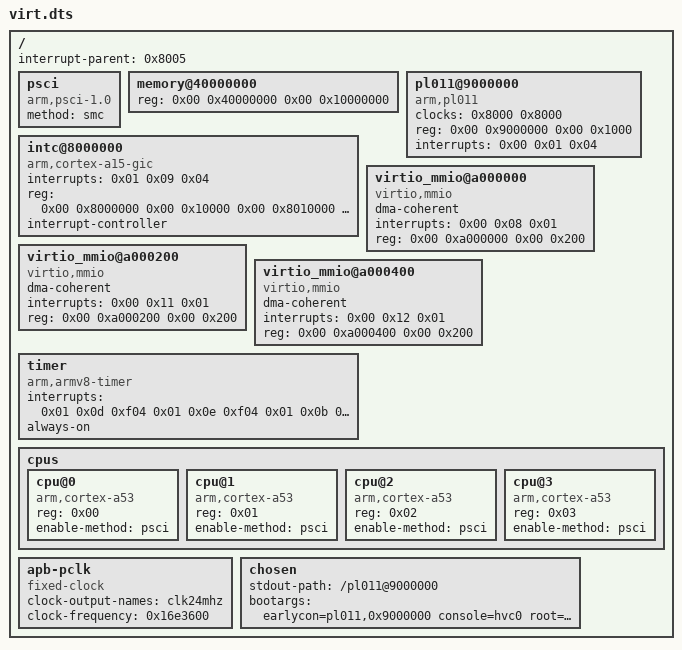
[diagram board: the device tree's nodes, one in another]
/dts-v1/;

/ {
	#size-cells = <0x02>;
	#address-cells = <0x02>;
	interrupt-parent = <0x8005>;

	psci {
		method = "smc";
		compatible = "arm,psci-1.0\0arm,psci-0.2\0arm,psci";
	};

	/* The size field (0x10000000) is only a placeholder: the hypervisor
	 * computes the guest RAM size at boot from the host's usable RAM and
	 * the number of physical CPUs, and rewrites this reg entry when
	 * loading this DTB into guest RAM (see vm.rs `create_vm`). */
	memory@40000000 {
		reg = <0x00 0x40000000 0x00 0x10000000>;
		device_type = "memory";
	};

	pl011@9000000 {
		clock-names = "uartclk\0apb_pclk";
		clocks = <0x8000 0x8000>;
		reg = <0x00 0x9000000 0x00 0x1000>;
		interrupts = <0x00 0x01 0x04>;
		compatible = "arm,pl011\0arm,primecell";
	};

	intc@8000000 {
		#interrupt-cells = <0x03>;
		phandle = <0x8005>;
		interrupts = <0x01 0x09 0x04>;
		reg = <0x00 0x8000000 0x00 0x10000 0x00 0x8010000 0x00 0x10000 0x00 0x8030000 0x00 0x10000 0x00 0x8040000 0x00 0x10000>;
		compatible = "arm,cortex-a15-gic";
		interrupt-controller;
	};

	virtio_mmio@a000000 {
		dma-coherent;
		interrupts = <0x00 0x08 0x01>;
		reg = <0x00 0xa000000 0x00 0x200>;
		compatible = "virtio,mmio";
	};

	virtio_mmio@a000200 {
		dma-coherent;
		interrupts = <0x00 0x11 0x01>;
		reg = <0x00 0xa000200 0x00 0x200>;
		compatible = "virtio,mmio";
	};

	virtio_mmio@a000400 {
		dma-coherent;
		interrupts = <0x00 0x12 0x01>;
		reg = <0x00 0xa000400 0x00 0x200>;
		compatible = "virtio,mmio";
	};

	timer {
		interrupts = <0x01 0x0d 0xf04 0x01 0x0e 0xf04 0x01 0x0b 0xf04 0x01 0x0a 0xf04>;
		always-on;
		compatible = "arm,armv8-timer\0arm,armv7-timer";
	};

	cpus {
		#size-cells = <0x00>;
		#address-cells = <0x01>;
		cpu@0 {
			phandle = <0x8004>;
			reg = <0x00>;
			enable-method = "psci";
			compatible = "arm,cortex-a53";
			device_type = "cpu";
		};

		cpu@1 {
			reg = <0x01>;
			enable-method = "psci";
			compatible = "arm,cortex-a53";
			device_type = "cpu";
		};

		cpu@2 {
			reg = <0x02>;
			enable-method = "psci";
			compatible = "arm,cortex-a53";
			device_type = "cpu";
		};

		cpu@3 {
			reg = <0x03>;
			enable-method = "psci";
			compatible = "arm,cortex-a53";
			device_type = "cpu";
		};
	};

	apb-pclk {
		phandle = <0x8000>;
		clock-output-names = "clk24mhz";
		clock-frequency = <0x16e3600>;
		#clock-cells = <0x00>;
		compatible = "fixed-clock";
	};

	chosen {
		stdout-path = "/pl011@9000000";
		/* rootflags=init_itable=0: every `cargo run-qemu` re-copies the
		 * pristine buildroot rootfs into disk.img, so ext4's lazyinit would
		 * otherwise re-zero all inode tables through the emulated virtio-blk
		 * on *every* boot (observed: several minutes to reach a login
		 * prompt with the 256MiB rootfs). Skipping the background zeroing
		 * is safe -- ext4 zeroes inode tables on demand at allocation time. */
		/* console=hvc0: the login console is the emulated virtio-console
		 * (batched virtqueue I/O) instead of the emulated PL011, which costs
		 * two EL2 MMIO traps per character under TCG. earlycon stays on the
		 * PL011 so early kernel messages still appear before virtio probing. */
		bootargs = "earlycon=pl011,0x9000000 console=hvc0 root=/dev/vda rootflags=init_itable=0";
	};
};

